AUTOSAR XML (schema 4-0-3)
package /ComponentTypes
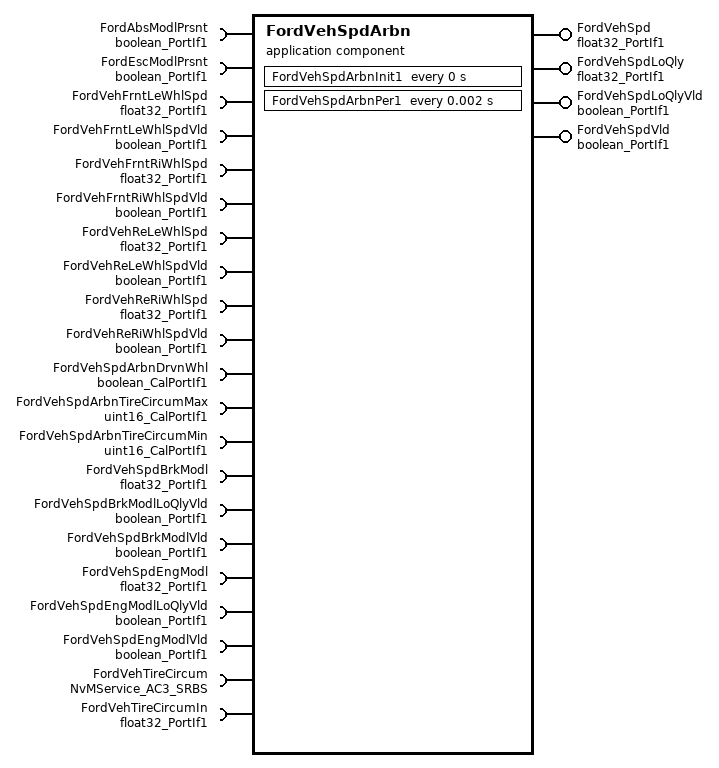
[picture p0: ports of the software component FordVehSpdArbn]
  application sw component type FordVehSpdArbn
    4 x provide port:
      FordVehSpd: nonqueued-sender-com-spec{data-element=Val, init-value=0}, provided-interface=float32_PortIf1
      FordVehSpdLoQly: nonqueued-sender-com-spec{data-element=Val, init-value=0}, provided-interface=float32_PortIf1
      FordVehSpdLoQlyVld: nonqueued-sender-com-spec{data-element=Logl, init-value=0}, provided-interface=boolean_PortIf1
      FordVehSpdVld: nonqueued-sender-com-spec{data-element=Logl, init-value=0}, provided-interface=boolean_PortIf1
    21 x require port:
      FordAbsModlPrsnt: nonqueued-receiver-com-spec{data-element=Logl, filter=data-filter-type=ALWAYS, init-value=0}, required-interface=boolean_PortIf1
      FordEscModlPrsnt: nonqueued-receiver-com-spec{data-element=Logl, filter=data-filter-type=ALWAYS, init-value=0}, required-interface=boolean_PortIf1
      FordVehFrntLeWhlSpd: nonqueued-receiver-com-spec{data-element=Val, filter=data-filter-type=ALWAYS, init-value=0}, required-interface=float32_PortIf1
      FordVehFrntLeWhlSpdVld: nonqueued-receiver-com-spec{data-element=Logl, filter=data-filter-type=ALWAYS, init-value=0}, required-interface=boolean_PortIf1
      FordVehFrntRiWhlSpd: nonqueued-receiver-com-spec{data-element=Val, filter=data-filter-type=ALWAYS, init-value=0}, required-interface=float32_PortIf1
      FordVehFrntRiWhlSpdVld: nonqueued-receiver-com-spec{data-element=Logl, filter=data-filter-type=ALWAYS, init-value=0}, required-interface=boolean_PortIf1
      FordVehReLeWhlSpd: nonqueued-receiver-com-spec{data-element=Val, filter=data-filter-type=ALWAYS, init-value=0}, required-interface=float32_PortIf1
      FordVehReLeWhlSpdVld: nonqueued-receiver-com-spec{data-element=Logl, filter=data-filter-type=ALWAYS, init-value=0}, required-interface=boolean_PortIf1
      FordVehReRiWhlSpd: nonqueued-receiver-com-spec{data-element=Val, filter=data-filter-type=ALWAYS, init-value=0}, required-interface=float32_PortIf1
      FordVehReRiWhlSpdVld: nonqueued-receiver-com-spec{data-element=Logl, filter=data-filter-type=ALWAYS, init-value=0}, required-interface=boolean_PortIf1
      FordVehSpdArbnDrvnWhl: parameter-require-com-spec{init-value=0, parameter=Logl}, required-interface=boolean_CalPortIf1
      FordVehSpdArbnTireCircumMax: parameter-require-com-spec{init-value=2500, parameter=Val}, required-interface=uint16_CalPortIf1
      FordVehSpdArbnTireCircumMin: parameter-require-com-spec{init-value=1500, parameter=Val}, required-interface=uint16_CalPortIf1
      FordVehSpdBrkModl: nonqueued-receiver-com-spec{data-element=Val, filter=data-filter-type=ALWAYS, init-value=0}, required-interface=float32_PortIf1
      FordVehSpdBrkModlLoQlyVld: nonqueued-receiver-com-spec{data-element=Logl, filter=data-filter-type=ALWAYS, init-value=0}, required-interface=boolean_PortIf1
      FordVehSpdBrkModlVld: nonqueued-receiver-com-spec{data-element=Logl, filter=data-filter-type=ALWAYS, init-value=0}, required-interface=boolean_PortIf1
      FordVehSpdEngModl: nonqueued-receiver-com-spec{data-element=Val, filter=data-filter-type=ALWAYS, init-value=0}, required-interface=float32_PortIf1
      FordVehSpdEngModlLoQlyVld: nonqueued-receiver-com-spec{data-element=Logl, filter=data-filter-type=ALWAYS, init-value=0}, required-interface=boolean_PortIf1
      FordVehSpdEngModlVld: nonqueued-receiver-com-spec{data-element=Logl, filter=data-filter-type=ALWAYS, init-value=0}, required-interface=boolean_PortIf1
      FordVehTireCircum: required-com-specs=[EraseBlock, GetErrorStatus, InvalidateNvBlock, ReadBlock, SetRamBlockStatus, WriteBlock], required-interface=NvMService_AC3_SRBS
      FordVehTireCircumIn: nonqueued-receiver-com-spec{data-element=Val, filter=data-filter-type=ALWAYS, init-value=0}, required-interface=float32_PortIf1
    behavior FordVehSpdArbn_InternalBehavior
      ar-typed-per-instance-memorys:
        data FordVehTireCircum: sw-calibration-access=READ-ONLY, type=uint16
      timing event FordVehSpdArbn_InitEvent: start-on-event=FordVehSpdArbnInit1, period=0
      timing event TMT_FordVehSpdArbnPer1: start-on-event=FordVehSpdArbnPer1, period=0.002
      explicit-inter-runnable-variables:
        data FordVehArbnTireCircum: type=uint16, init-value=65534
      port-api-options:
        enable-take-address=false, indirect-api=false, port=FordAbsModlPrsnt
        enable-take-address=false, indirect-api=false, port=FordEscModlPrsnt
      runnable FordVehSpdArbnInit1
        sync call SC_FordVehTireCircum_GetErrorStatus: operation=FordVehTireCircum.GetErrorStatus, timeout=0
        written-local-variables:
          access WRITE_FordVehArbnTireCircum: accessed-variable=FordVehArbnTireCircum
      runnable FordVehSpdArbnPer1
        data-receive-point-by-arguments:
          17 x access:
            REC_float32_PortIf1_Val: accessed-variable=FordVehTireCircumIn.Val
            REC_FordAbsModlPrsnt_Logl: accessed-variable=FordAbsModlPrsnt.Logl
            REC_FordEscModlPrsnt_Logl: accessed-variable=FordEscModlPrsnt.Logl
            REC_FordVehFrntLeWhlSpd_Val: accessed-variable=FordVehFrntLeWhlSpd.Val
            REC_FordVehFrntLeWhlSpdVld_Logl: accessed-variable=FordVehFrntLeWhlSpdVld.Logl
            REC_FordVehFrntRiWhlSpd_Val: accessed-variable=FordVehFrntRiWhlSpd.Val
            REC_FordVehFrntRiWhlSpdVld_Logl: accessed-variable=FordVehFrntRiWhlSpdVld.Logl
            REC_FordVehReLeWhlSpd_Val: accessed-variable=FordVehReLeWhlSpd.Val
            REC_FordVehReLeWhlSpdVld_Logl: accessed-variable=FordVehReLeWhlSpdVld.Logl
            REC_FordVehReRiWhlSpd_Val: accessed-variable=FordVehReRiWhlSpd.Val
            REC_FordVehReRiWhlSpdVld_Logl: accessed-variable=FordVehReRiWhlSpdVld.Logl
            REC_FordVehSpdBrkModl_Val: accessed-variable=FordVehSpdBrkModl.Val
            REC_FordVehSpdBrkModlLoQlyVld_Logl: accessed-variable=FordVehSpdBrkModlLoQlyVld.Logl
            REC_FordVehSpdBrkModlVld_Logl: accessed-variable=FordVehSpdBrkModlVld.Logl
            REC_FordVehSpdEngModl_Val: accessed-variable=FordVehSpdEngModl.Val
            REC_FordVehSpdEngModlLoQlyVld_Logl: accessed-variable=FordVehSpdEngModlLoQlyVld.Logl
            REC_FordVehSpdEngModlVld_Logl: accessed-variable=FordVehSpdEngModlVld.Logl
        data-send-points:
          4 x access:
            SEND_FordVehSpd_Val: accessed-variable=FordVehSpd.Val
            SEND_FordVehSpdLoQly_Val: accessed-variable=FordVehSpdLoQly.Val
            SEND_FordVehSpdLoQlyVld_Logl: accessed-variable=FordVehSpdLoQlyVld.Logl
            SEND_FordVehSpdVld_Logl: accessed-variable=FordVehSpdVld.Logl
        read-local-variables:
          access READ_FordVehArbnTireCircum: accessed-variable=FordVehArbnTireCircum
        sync call SC_FordVehTireCircum_SetRamBlockStatus: operation=FordVehTireCircum.SetRamBlockStatus, timeout=0
      swc service dependency NvmFordVehTireCircum: assigned-datas=role-based-data-assignment={role=ramBlock, used-data-element=FordVehTireCircum}, assigned-ports=role-based-port-assignment={port-prototype=FordVehTireCircum, role=NvMService_AC3_SRBS}
        service-needs:
          nv block needs NvmFordVehTireCircum: n-data-sets=0, reliability=ERROR-DETECTION, resistant-to-changed-sw=true, restore-at-start=true, store-at-shutdown=true
  swc implementation FordVehSpdArbn_Implementation: behavior=FordVehSpdArbn_InternalBehavior
    code-descriptors:
      code Default: artifact-descriptors=autosar-engineering-object={short-label=Default, category=SWSRC}
